# STM32N645 register map
File version: 1.0
CPU: CM55 r0p1, little endian, no MPU, FPU, vendor SysTick, 8 interrupt priority bits
Registers are 32-bit, read-write, reset 0x0 unless marked. A register's access mark holds for its fields unless they carry their own. Offsets are from the block's base; [hi:lo] are bit positions; 'fields as' and 'values as' point back to an identical list.

## RAMCFG — SRAM configuration controller
Base 0x42023000
Same registers: RAMCFG_S 0x52023000
0x00 RAMCFG_AXISRAM1CR — RAMCFG AXISRAM1 control register
  [8] SRAMER — SRAM erase.
    0=No erase operation ongoing; 1=Erase operation ongoing
0x08 RAMCFG_AXISRAM1ISR ro — RAMCFG AXISRAM1 interrupt status register
  [8] SRAMBUSY — SRAM busy with erase operation
    0=No erase operation ongoing; 1=Erase operation ongoing
0x28 RAMCFG_AXISRAM1ERKEYR wo — RAMCFG AXISRAM1 erase key register
  [7:0] ERASEKEY — Erase write protection key
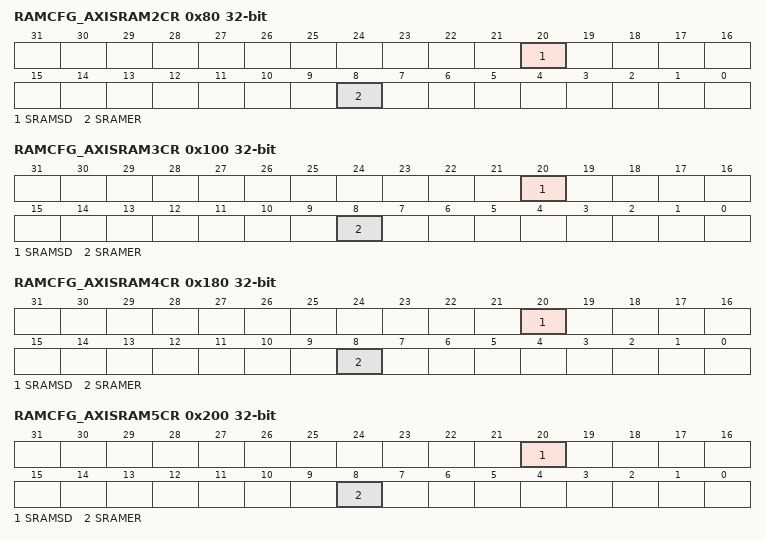
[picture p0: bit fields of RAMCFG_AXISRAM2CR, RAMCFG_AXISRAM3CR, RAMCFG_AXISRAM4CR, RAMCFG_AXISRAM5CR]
0x80 RAMCFG_AXISRAM2CR — RAMCFG AXISRAM2 control register
  [20] SRAMSD — Shutdown AXISRAMx
    0=AXISRAMx memory is powered; 1=AXISRAMx memory is in shutdown, and its content is not retained
  [8] SRAMER — SRAM erase
    0=No erase operation ongoing; 1=Erase operation ongoing
0x88 RAMCFG_AXISRAM2ISR ro — RAMCFG AXISRAM2 interrupt status register
  fields as RAMCFG_AXISRAM1ISR
0xA8 RAMCFG_AXISRAM2ERKEYR wo — RAMCFG AXISRAM2 erase key register
  [7:0] ERASEKEY — Erase write protection key
0x100 RAMCFG_AXISRAM3CR — RAMCFG AXISRAM3 control register
  fields as RAMCFG_AXISRAM2CR
0x108 RAMCFG_AXISRAM3ISR ro — RAMCFG AXISRAM3 interrupt status register
  fields as RAMCFG_AXISRAM1ISR
0x128 RAMCFG_AXISRAM3ERKEYR wo — RAMCFG AXISRAM3 erase key register
  [7:0] ERASEKEY — Erase write protection key
0x180 RAMCFG_AXISRAM4CR — RAMCFG AXISRAM4 control register
  fields as RAMCFG_AXISRAM2CR
0x188 RAMCFG_AXISRAM4ISR ro — RAMCFG AXISRAM4 interrupt status register
  fields as RAMCFG_AXISRAM1ISR
0x1A8 RAMCFG_AXISRAM4ERKEYR wo — RAMCFG AXISRAM4 erase key register
  [7:0] ERASEKEY — Erase write protection key
0x200 RAMCFG_AXISRAM5CR — RAMCFG AXISRAM5 control register
  fields as RAMCFG_AXISRAM2CR
0x208 RAMCFG_AXISRAM5ISR ro — RAMCFG AXISRAM5 interrupt status register
  fields as RAMCFG_AXISRAM1ISR
0x228 RAMCFG_AXISRAM5ERKEYR wo — RAMCFG AXISRAM5 erase key register
  [7:0] ERASEKEY — Erase write protection key
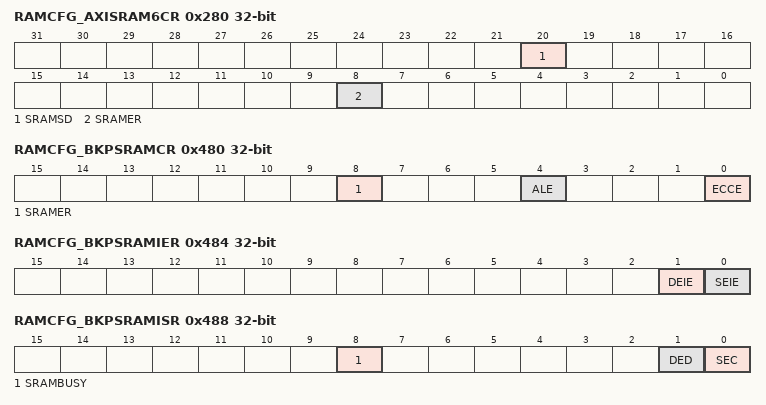
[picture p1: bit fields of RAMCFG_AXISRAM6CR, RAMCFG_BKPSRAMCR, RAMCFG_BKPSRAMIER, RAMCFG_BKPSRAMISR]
0x280 RAMCFG_AXISRAM6CR — RAMCFG AXISRAM6 control register
  fields as RAMCFG_AXISRAM2CR
0x288 RAMCFG_AXISRAM6ISR ro — RAMCFG AXISRAM6 interrupt status register
  fields as RAMCFG_AXISRAM1ISR
0x2A8 RAMCFG_AXISRAM6ERKEYR wo — RAMCFG AXISRAM6 erase key register
  [7:0] ERASEKEY — Erase write protection key
0x300 RAMCFG_AHBSRAM1CR — RAMCFG AHBSRAM1 control register
  [8] SRAMER — SRAM erase
    0=No erase operation ongoing; 1=Erase operation ongoing
0x308 RAMCFG_AHBSRAM1ISR ro — RAMCFG AHBSRAM1 interrupt status register
  fields as RAMCFG_AXISRAM1ISR
0x328 RAMCFG_AHBSRAM1ERKEYR wo — RAMCFG AHBSRAM1 erase key register
  [7:0] ERASEKEY — Erase write protection key
0x380 RAMCFG_AHBSRAM2CR — RAMCFG AHBSRAM2 control register
  fields as RAMCFG_AHBSRAM1CR
0x388 RAMCFG_AHBSRAM2ISR ro — RAMCFG AHBSRAM2 interrupt status register
  fields as RAMCFG_AXISRAM1ISR
0x3A8 RAMCFG_AHBSRAM2ERKEYR wo — RAMCFG AHBSRAM2 erase key register
  [7:0] ERASEKEY — Erase write protection key
0x400 RAMCFG_VENCRAMCR — RAMCFG VENCRAM control register
  fields as RAMCFG_AHBSRAM1CR
0x408 RAMCFG_VENCRAMISR ro — RAMCFG VENCRAM interrupt status register
  fields as RAMCFG_AXISRAM1ISR
0x428 RAMCFG_VENCRAMERKEYR wo — RAMCFG VENCRAM erase key register
  [7:0] ERASEKEY — Erase write protection key
0x480 RAMCFG_BKPSRAMCR — RAMCFG BKPSRAM control register
  [8] SRAMER — SRAM erase
    0=No erase operation ongoing; 1=Erase operation ongoing
  [4] ALE — Address latch enable
    0=Failing address not stored in RAMCFG_BKPSRAMESEAR or _BKPSRAMEDEAR; 1=Failing address stored in RAMCFG_BKPSRAMESEAR or _BKPSRAMEDEAR
  [0] ECCE — ECC enable
    0=ECC disabled; 1=ECC enabled
0x484 RAMCFG_BKPSRAMIER — RAMCFG BKPSRAM interrupt enable register
  [1] DEIE — ECC double error interrupt enable
    0=Double error interrupt disabled; 1=Double error interrupt enabled
  [0] SEIE — ECC single error interrupt enable
    0=Single error interrupt disabled; 1=Single error interrupt enabled
0x488 RAMCFG_BKPSRAMISR ro — RAMCFG BKPSRAM interrupt status register
  [8] SRAMBUSY — SRAM busy with erase operation
    0=No erase operation ongoing; 1=Erase operation ongoing
  [1] DED — ECC double-error interrupt enable
    0=No double error; 1=Double error detected
  [0] SEC — ECC single error detected
    0=No single error detected; 1=Single error detected and corrected
0x48C RAMCFG_BKPSRAMESEAR wo — RAMCFG BKPSRAM single error address register
  [10:0] ESEA — ECC single error address
0x490 RAMCFG_BKPSRAMEDEAR wo — RAMCFG BKPSRAM double error address register
  [10:0] EDEA — ECC double error address
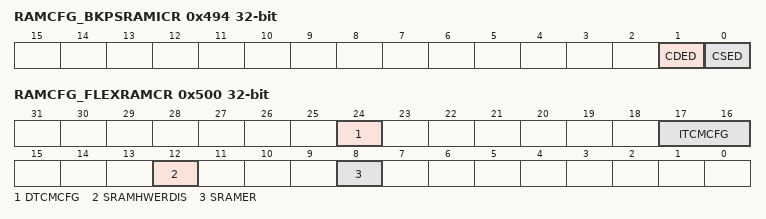
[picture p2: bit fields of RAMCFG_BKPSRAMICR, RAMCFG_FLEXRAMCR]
0x494 RAMCFG_BKPSRAMICR wo — RAMCFG BKPSRAM interrupt clear register
  [1] CDED — Clear ECC double-error interrupt
  [0] CSED — Clear ECC single-error interrupt
0x4A4 RAMCFG_BKPSRAMECCKEYR wo — RAMCFG BKPSRAM ECC key register
  [7:0] ECCKEY — ECC write protection key
0x4A8 RAMCFG_BKPSRAMERKEYR wo — RAMCFG BKPSRAM erase key register
  [7:0] ERASEKEY — Erase write protection key
0x500 RAMCFG_FLEXRAMCR — RAMCFG FLEXRAM control register
  [24] DTCMCFG — Configuration of the FLEXMEM D-TCM extension
    0=FLEXMEM D-TCM extension allocated as AXI RAM; 1=FLEXMEM D-TCM extension allocated as DTCM
  [17:16] ITCMCFG — Configuration of the FLEXMEM I-TCM extension
    0=FLEXMEM I-TCM extension entirely allocated as AXI RAM; 1=First 64 Kbytes (and corresponding ECC) allocated as I-TCM, remaining part allocated as AXI RAM; 2=FLEXMEM I-TCM extension entirely allocated as AXI RAM
  [12] SRAMHWERDIS — SRAM hardware erase disable
    0=Erase operation done after a system reset; 1=No erase operation done after a system reset, only for the retention part of the FLEXMEM when it is used as AXI RAM
  [8] SRAMER — SRAM erase
    0=No erase operation ongoing; 1=Erase operation ongoing
0x508 RAMCFG_FLEXRAMISR ro — RAMCFG FLEXRAM interrupt status register
  fields as RAMCFG_AXISRAM1ISR
0x528 RAMCFG_FLEXRAMERKEYR wo — RAMCFG FLEXRAM erase key register
  [7:0] ERASEKEY — Erase write protection key
